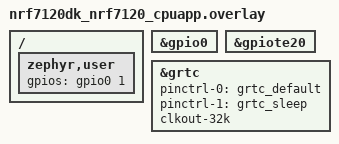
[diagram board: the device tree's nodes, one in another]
/*
 * Copyright (c) 2026 Nordic Semiconductor ASA
 *
 * SPDX-License-Identifier: LicenseRef-Nordic-5-Clause
 */

/* Required loopback between:
 * GPIO P0.01 and P0.02 (GRTC 32k; defined @board; no other option)
 */

/ {
	zephyr,user {
		gpios = <&gpio0 1 GPIO_ACTIVE_HIGH>;  /* Connect to dedicated GRTC output */
	};
};

&gpio0 {
	status = "okay";
};

&gpiote20 {
	status = "okay";
};

&grtc {
	pinctrl-0 = <&grtc_default>;
	pinctrl-1 = <&grtc_sleep>;
	pinctrl-names = "default", "sleep";
	clkout-32k;
};
